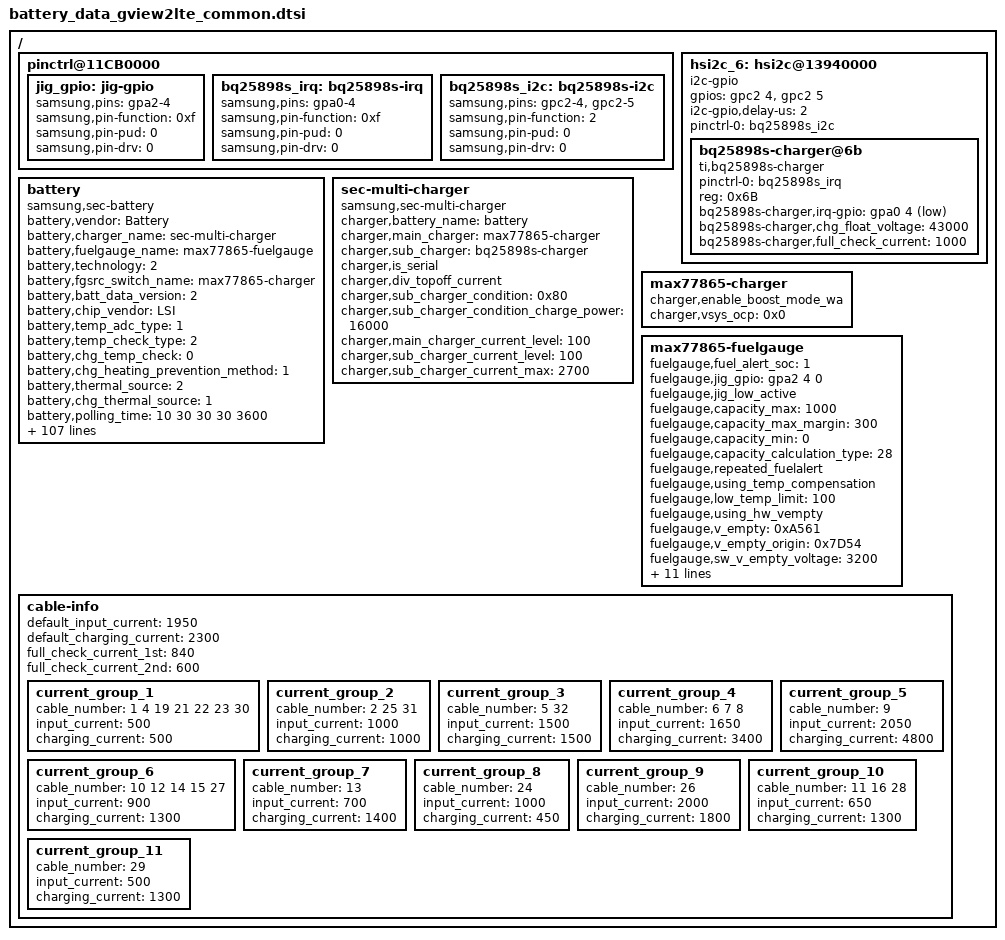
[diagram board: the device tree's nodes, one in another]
/*
 * Jackpot Battery parameters device tree file for board IDs 04 and higher
 *
 * Copyright (C) 2017 Samsung Electronics, Inc.
 *
 * This program is free software; you can redistribute it and/or
 * modify it under the terms of the GNU General Public License
 * as published by the Free Software Foundation; either version 2
 * of the License, or (at your option) any later version.
 *
 * This program is distributed in the hope that it will be useful,
 * but WITHOUT ANY WARRANTY; without even the implied warranty of
 * MERCHANTABILITY or FITNESS FOR A PARTICULAR PURPOSE.  See the
 * GNU General Public License for more details.
 *
 * You should have received a copy of the GNU General Public License
 * along with this program. If not, see <http://www.gnu.org/licenses/>.
 *
 */

/ {
	pinctrl@11CB0000 {
		jig_gpio: jig-gpio {
			samsung,pins = "gpa2-4";
			samsung,pin-function = <0xf>;
			samsung,pin-pud = <0>;
			samsung,pin-drv = <0>;
		};
		
		bq25898s_irq: bq25898s-irq {
			samsung,pins = "gpa0-4";
			samsung,pin-function = <0xf>;
			samsung,pin-pud = <0>;
			samsung,pin-drv = <0>;
		};

		bq25898s_i2c: bq25898s-i2c {
			samsung,pins = "gpc2-4", "gpc2-5";
			samsung,pin-function = <2>;
			samsung,pin-pud = <0>;
			samsung,pin-drv = <0>;
		};
	};

	hsi2c_6: hsi2c@13940000 { /* hsi2c 6 */
		compatible = "i2c-gpio";
		gpios = <&gpc2 4 0 /* sda */
                 &gpc2 5 0 /* scl */>;
		i2c-gpio,delay-us = <2>;
		status = "okay";
		#address-cells = <1>;
		#size-cells = <0>;
		pinctrl-names = "default";
		pinctrl-0 = <&bq25898s_i2c>;

		bq25898s-charger@6b {
			compatible = "ti,bq25898s-charger";
			pinctrl-names = "default";
			pinctrl-0 = <&bq25898s_irq>;
			reg = <0x6B>;
			bq25898s-charger,irq-gpio = <&gpa0 4 1>;
			bq25898s-charger,chg_float_voltage = <43000>;
			bq25898s-charger,full_check_current = <1000>;
		};
	};

	battery {
		status = "okay";
		compatible = "samsung,sec-battery";

		pinctrl-names = "default";
		/* battery,irq_gpio = <&gpa1 6 0>; */

		battery,vendor = "Battery";
		battery,charger_name = "sec-multi-charger";
		battery,fuelgauge_name = "max77865-fuelgauge";
		battery,technology = <2>; /* POWER_SUPPLY_TECHNOLOGY_LION */
		battery,fgsrc_switch_name = "max77865-charger"; /* Fuelgauge voltage source */

		battery,batt_data_version = <2>;

		battery,chip_vendor = "LSI";
		battery,temp_adc_type = <1>; /* SEC_BATTERY_ADC_TYPE_AP */

		battery,temp_check_type = <2>; /* SEC_BATTERY_TEMP_CHECK_TEMP */
		battery,chg_temp_check = <0>;
		battery,chg_heating_prevention_method = <1>; /* SEC_BATTERY_BY_CHANGING_CURRENT */

		battery,thermal_source = <2>; /* SEC_BATTERY_THERMAL_SOURCE_ADC */
		battery,chg_thermal_source = <1>;

		battery,polling_time = <10 30 30 30 3600>;

		battery,temp_table_adc = <303 311 319 327 335 343 351 359 367 375
				383 397 411 425 439 453 473 493 513 533
				553 574 596 617 639 661 684 707 730 753
				776 799 823 847 870 894 916 937 959 980
				1002 1026 1049 1073 1096 1120 1166 1212 1258 1304
				1350 1395 1440 1485 1530 1575 1615 1655 1695 1735
				1775 1826 1877 1928 1979 2030 2076 2122 2167 2213
				2259 2304 2350 2395 2440 2486 2529 2573 2616 2660
				2704 2745 2787 2829 2870 2912 2944 2977 3009 3042
				3074
				3091 3107 3124 3141 3158 3185 3213 3241 3269 3297
				3322 3347 3372 3397 3422 3435 3448 3461 3474 3488>;

		battery,temp_table_data = <900 890 880 870 860 850 840 830 820 810
				800 790 780 770 760 750 740 730 720 710
				700 690 680 670 660 650 640 630 620 610
				600 590 580 570 560 550 540 530 520 510
				500 490 480 470 460 450 440 430 420 410
				400 390 380 370 360 350 340 330 320 310
				300 290 280 270 260 250 240 230 220 210
				200 190 180 170 160 150 140 130 120 110
				100 90 80 70 60 50 40 30 20 10
				0
				(-10) (-20) (-30) (-40) (-50) (-60) (-70) (-80) (-90) (-100)
				(-110) (-120) (-130) (-140) (-150) (-160) (-170) (-180) (-190) (-200)>;

		battery,chg_temp_table_adc = <270 278 286 294 302 310 318 326 334 342
				350 364 378 392 406 420 440 460 480 500
				520 540 560 581 601 621 643 664 686 707
				729 751 773 795 818 840 866 891 917 943
				969 998 1028 1058 1088 1118 1153 1189 1225 1261
				1297 1336 1375 1414 1453 1493 1532 1572 1612 1652
				1692 1737 1781 1826 1870 1915 1956 1998 2039 2081
				2123 2165 2208 2250 2293 2336 2379 2423 2467 2510
				2554 2594 2634 2673 2713 2753 2787 2822 2856 2890
				2925
				2960 2995 3030 3065 3101 3130 3160 3189 3219 3249
				3275 3302 3328 3355 3382 3396 3410 3424 3438 3452>;

		battery,chg_temp_table_data = <900 890 880 870 860 850 840 830 820 810
				800 790 780 770 760 750 740 730 720 710
				700 690 680 670 660 650 640 630 620 610
				600 590 580 570 560 550 540 530 520 510
				500 490 480 470 460 450 440 430 420 410
				400 390 380 370 360 350 340 330 320 310
				300 290 280 270 260 250 240 230 220 210
				200 190 180 170 160 150 140 130 120 110
				100 90 80 70 60 50 40 30 20 10
				0
				(-10) (-20) (-30) (-40) (-50) (-60) (-70) (-80) (-90) (-100)
				(-110) (-120) (-130) (-140) (-150) (-160) (-170) (-180) (-190) (-200)>;

		battery,adc_check_count = <5>;

		battery,cable_check_type = <64>; /* SEC_BATTERY_CABLE_CHECK_USBBUCKOFF */
		battery,cable_source_type = <1>; /* SEC_BATTERY_CABLE_SOURCE_EXTERNAL */
		battery,polling_type = <1>; /* SEC_BATTERY_MONITOR_ALARM */
		battery,monitor_initial_count = <0>;

		battery,battery_check_type = <0>; /* SEC_BATTERY_CHECK_NONE */
		battery,check_count = <0>;
		battery,check_adc_max = <1440>;
		battery,check_adc_min = <0>;

		battery,ovp_uvlo_check_type = <3>; /* SEC_BATTERY_OVP_UVLO_CHGPOLLING */

		battery,temp_check_count = <1>;
		battery,temp_highlimit_threshold_event = <800>;
		battery,temp_highlimit_recovery_event = <750>;
		battery,temp_high_threshold_event = <500>;
		battery,temp_high_recovery_event = <450>;
		battery,temp_low_threshold_event = <0>;
		battery,temp_low_recovery_event = <50>;
		battery,temp_highlimit_threshold_normal = <800>;
		battery,temp_highlimit_recovery_normal = <750>;
		battery,temp_high_threshold_normal = <500>;
		battery,temp_high_recovery_normal = <450>;
		battery,temp_low_threshold_normal = <0>;
		battery,temp_low_recovery_normal = <50>;
		battery,temp_highlimit_threshold_lpm = <800>;
		battery,temp_highlimit_recovery_lpm = <750>;
		battery,temp_high_threshold_lpm = <500>;
		battery,temp_high_recovery_lpm = <450>;
		battery,temp_low_threshold_lpm = <0>;
		battery,temp_low_recovery_lpm = <50>;
		battery,full_check_type = <2>; /* SEC_BATTERY_FULLCHARGED_FG_CURRENT */
		battery,full_check_type_2nd = <2>; /* SEC_BATTERY_FULLCHARGED_FG_CURRENT */
		battery,full_check_count = <2>;
		battery,chg_gpio_full_check = <0>;
		battery,chg_polarity_full_check = <1>;

		battery,chg_high_temp = <490>;
		battery,chg_high_temp_recovery = <470>;
		battery,chg_input_limit_current = <1000>;
		battery,chg_charging_limit_current = <1500>;

		battery,mix_high_temp = <420>;
		battery,mix_high_chg_temp = <500>;
		battery,mix_high_temp_recovery = <390>;

		/* SEC_BATTERY_FULL_CONDITION_NOTIMEFULL |
		   SEC_BATTERY_FULL_CONDITION_VCELL */
		battery,full_condition_type = <9>;
		battery,full_condition_soc = <93>;
		battery,full_condition_vcell = <4200>;

		battery,recharge_check_count = <1>;
		battery,recharge_condition_type = <4>; /* SEC_BATTERY_RECHARGE_CONDITION_VCELL */
		battery,recharge_condition_soc = <98>;
		battery,recharge_condition_vcell = <4230>;

		battery,charging_total_time = <14400>;
		battery,hv_charging_total_time = <10800>;
		battery,normal_charging_total_time = <18000>;
		battery,usb_charging_total_time = <36000>;
		battery,recharging_total_time = <5400>;
		battery,charging_reset_time = <0>;

		battery,chg_float_voltage = <43000>;
		battery,chg_float_voltage_conv = <10>;

		battery,swelling_high_temp_block = <410>;
		battery,swelling_high_temp_recov = <390>;
		battery,swelling_low_temp_block_1st = <150>;
		battery,swelling_low_temp_recov_1st = <200>;
		battery,swelling_low_temp_block_2nd = <50>;
		battery,swelling_low_temp_recov_2nd = <100>;

		battery,swelling_low_temp_current = <1800>;	/* 0.3C */
		battery,swelling_low_temp_topoff = <600>;	/* 0.05C */
		battery,swelling_high_temp_current = <2700>;	/* 0.45C */
		battery,swelling_high_temp_topoff = <600>;	/* 0.05C */

		battery,swelling_drop_float_voltage = <41000>;
		battery,swelling_high_rechg_voltage = <3950>;
		battery,swelling_low_rechg_voltage = <3950>;

		battery,siop_event_check_type = <1>;
		battery,siop_call_cv_current = <330>;
		battery,siop_call_cc_current = <330>;

		battery,siop_input_limit_current = <1950>;
		battery,siop_charging_limit_current = <1610>;
		battery,siop_hv_input_limit_current = <1650>;
		battery,siop_hv_charging_limit_current = <2380>;
		battery,siop_hv_12v_input_limit_current = <2050>;
		battery,siop_hv_12v_charging_limit_current = <3360>;

		battery,siop_default_power = <16000>;

		battery,ttf_hv_charge_current = <4800>;

		battery,pd_charging_charge_power = <25000>;
		battery,max_charging_current = <4800>;
		battery,slow_charging_current = <999>;
		battery,battery_full_capacity = <12000>;

		/* cycle, chg_float_voltage, recharge_condition_vcell, full_condition_vcell, full_condition_soc */
		battery,age_data = <0 43000 4230 4200 93	/*4.30*/
				200 42800 4210 4180 92	/*4.28*/
				250 42600 4190 4160 91	/*4.26*/
				300 42400 4170 4140 90	/*4.24*/
				1000 41900 4120 4090 89	/*4.19*/
				>;

		battery,max_input_voltage = <12000>; /* mV */
		battery,max_input_current = <3000>;  /* mA */

		battery,pre_afc_work_delay = <3000>;

		battery,enable_sysovlo_irq;
		battery,enable_water_resistance;

		battery,standard_curr = <4800>;
		battery,expired_time = <17400>;
		battery,recharging_expired_time = <5400>;

		battery,cisd_max_voltage_thr = <4400>; /* battery ovp detection voltage */

		battery,cisd_alg_index = <7>;

		io-channels = <&exynos_adc 1>, <&exynos_adc 2>;
		io-channel-names = "adc-temp", "adc-chg-temp";
		#io-channel-cells = <2>;
		io-channel-ranges;
	};

	sec-multi-charger {
		status = "okay";
		compatible = "samsung,sec-multi-charger";

		charger,battery_name = "battery";
		charger,main_charger = "max77865-charger";
		charger,sub_charger = "bq25898s-charger";

		charger,is_serial;
		charger,div_topoff_current;

		charger,sub_charger_condition = <0x80>;
		charger,sub_charger_condition_charge_power = <16000>;

		charger,main_charger_current_level = <100>;
		charger,sub_charger_current_level = <100>;

		charger,sub_charger_current_max = <2700>;
	};

	max77865-charger {
		charger,enable_boost_mode_wa;
		charger,vsys_ocp = /bits/ 8 <0x0>;	/* Disable */
	};

	max77865-fuelgauge {
		status = "okay";
		fuelgauge,fuel_alert_soc = <1>;
		fuelgauge,jig_gpio = <&gpa2 4 0>;
		fuelgauge,jig_low_active;
		fuelgauge,capacity_max = <1000>;
		fuelgauge,capacity_max_margin = <300>;
		fuelgauge,capacity_min = <0>;
		fuelgauge,capacity_calculation_type = <28>;
		fuelgauge,repeated_fuelalert;
		fuelgauge,using_temp_compensation;
		fuelgauge,low_temp_limit = <100>;
		fuelgauge,using_hw_vempty;
		fuelgauge,v_empty = <0xA561>; /* Empty: 3260mV, Recover: 3480mV */
		fuelgauge,v_empty_origin = <0x7D54>; /* Empty: 2500mV, Recover: 3360mV */
		fuelgauge,sw_v_empty_voltage = <3200>;
		fuelgauge,sw_v_empty_voltage_cisd = <3100>;
		fuelgauge,sw_v_empty_recover_voltage = <3480>;
		fuelgauge,qrtable20 = <0x1686>;
		fuelgauge,qrtable30 = <0x1208>;
		fuelgauge,fg_resistor = <2>;
		fuelgauge,capacity = <0x2CE2>;
		/*fuelgauge,auto_discharge_en;*/
		fuelgauge,discharge_temp_threshold = <600>;
		fuelgauge,discharge_volt_threshold = <4200>;
		fuelgauge,ttf_capacity = <12000>;
		fuelgauge,cv_data = <
			2488	829	1809
			2409	832	1796
			2327	837	1769
			2272	840	1743
			2182	846	1721
			2104	850	1690
			2038	854	1670
			1950	859	1640
			1904	861	1622
			1838	865	1594
			1797	867	1576
			1749	870	1560
			1703	873	1531
			1683	873	1525
			1667	875	1515
			1660	875	1512
			1653	876	1509
			1615	878	1502
			1580	880	1483
			1553	881	1463
			1544	882	1458
			1520	883	1451
			1477	886	1424
			1431	888	1409
			1396	891	1383
			1347	894	1361
			1299	896	1332
			1267	898	1315
			1231	902	1288
			1202	904	1263
			1148	906	1243
			1109	909	1213
			1067	911	1185
			1031	914	1156
			1013	915	1140
			975	917	1111
			961	919	1084
			921	921	1064
			892	923	1038
			887	923	1019
			863	925	1004
			833	927	976
			808	929	946
			787	930	918
			780	931	904
			764	932	895
			744	934	864
			730	935	846
			715	936	828
			693	937	800
			681	938	783
			666	940	752
			651	941	735
			640	942	712
			628	945	697
			622	946	679
			618	947	664
			600	950	646
			596	951	627
			589	953	614
			584	953	601
			576	956	572
			577	957	553
			562	958	535
			511	968	506
			505	969	487
			493	971	464
			492	972	435
			484	973	417
			480	975	398
			474	976	380
			470	977	364
			462	977	355
			456	978	336
			452	979	329
			446	981	303
			437	982	282
			429	984	255
			423	985	242
			422	986	229
			414	987	211
			411	988	199
			405	989	191
			397	990	171
			391	991	140
			387	992	126
			384	993	107
			372	995	84
			364	997	54
			356	998	26
			356	998	13
			0	1000	0
			>;
	};

/* sec_battery_cable
 *   0	UNKNOWN,
 *   1	NONE,
 *   2	PREPARE_TA,
 *   3	TA,
 *   4	USB,
 *   5	USB_CDP,
 *   6	9V_TA,
 *   7	9V_ERR,
 *   8	9V_UNKNOWN,
 *   9	12V_TA,
 *  10	WIRELESS,
 *  11	HV_WIRELESS,
 *  12	PMA_WIRELESS,
 *  13	WIRELESS_PACK,
 *  14	WIRELESS_PACK_TA,
 *  15	WIRELESS_STAND,
 *  16	WIRELESS_HV_STAND,
 *  17	QC20,
 *  18	QC30,
 *  19	PDIC,
 *  20	UARTOFF,
 *  21	OTG,
 *  22	LAN_HUB,
 *  23	POWER_SHARING,
 *  24	HMT_CONNECTED,
 *  25	HMT_CHARGE,
 *  26	HV_TA_CHG_LIMIT,
 *  27	WIRELESS_VEHICLE,
 *  28	WIRELESS_HV_VEHICLE,
 *  29	PREPARE_WIRELESS_HV,
 *  30	TIMEOUT,
 *  31  SMART_OTG,
 *  32  SMART_NOTG,
 *  33	CABLE_MAX,
*/
	cable-info {
		   default_input_current = <1950>;
		   default_charging_current = <2300>;
		   full_check_current_1st = <840>;
		   full_check_current_2nd = <600>;

		   current_group_1 {
		   	       cable_number = <1 4 19 21 22 23 30>;
			       input_current = <500>;
			       charging_current = <500>;
		   };
		   current_group_2 {
		   	       cable_number = <2 25 31>;
			       input_current = <1000>;
			       charging_current = <1000>;
		  };
		   current_group_3 {
		   	       cable_number = <5 32>;
			       input_current = <1500>;
			       charging_current = <1500>;
		  };
		   current_group_4 {
		   	       cable_number = <6 7 8>;
			       input_current = <1650>;
			       charging_current = <3400>;
		  };
		   current_group_5 {
		   	       cable_number = <9>;
			       input_current = <2050>;
			       charging_current = <4800>;
		  };
		   current_group_6 {
		   	       cable_number = <10 12 14 15 27>;
			       input_current = <900>;
			       charging_current = <1300>;
		  };
		   current_group_7 {
		   	       cable_number = <13>;
			       input_current = <700>;
			       charging_current = <1400>;
		  };
		   current_group_8 {
		   	       cable_number = <24>;
			       input_current = <1000>;
			       charging_current = <450>;
		  };
		   current_group_9 {
		   	       cable_number = <26>;
			       input_current = <2000>;
			       charging_current = <1800>;
		  };
		   current_group_10 {
		   	       cable_number = <11 16 28>;
			       input_current = <650>;
			       charging_current = <1300>;
		  };
		   current_group_11 {
		   	       cable_number = <29>;
			       input_current = <500>;
			       charging_current = <1300>;
		  };
	};
};
